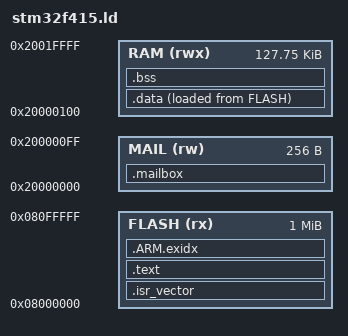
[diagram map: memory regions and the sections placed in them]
ENTRY(Reset_Handler)
MEMORY { FLASH (rx) : ORIGIN = 0x08000000, LENGTH = 1024K
         MAIL (rw) : ORIGIN = 0x20000000, LENGTH = 256
         RAM (rwx) : ORIGIN = 0x20000100, LENGTH = 128K - 256 }
_estack = ORIGIN(RAM) + LENGTH(RAM);
SECTIONS {
 .isr_vector : { KEEP(*(.isr_vector)) } > FLASH
 .text : { *(.text*) *(.rodata*) . = ALIGN(4); } > FLASH
 .ARM.exidx : { *(.ARM.exidx*) } > FLASH
 .mailbox (NOLOAD) : { KEEP(*(.mailbox)) } > MAIL
 .data : { . = ALIGN(4); _sdata = .; *(.data*) . = ALIGN(4); _edata = .; } > RAM AT > FLASH
 _sidata = LOADADDR(.data);
 .bss (NOLOAD) : { . = ALIGN(4); _sbss = .; *(.bss*) *(COMMON) . = ALIGN(4); _ebss = .; } > RAM
 /DISCARD/ : { *(.comment) *(.note*) }
}
